AUTOSAR XML (schema 4-2-2)
package /COM_SWC
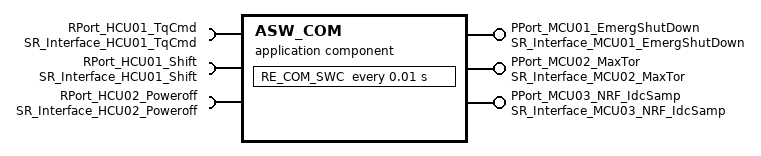
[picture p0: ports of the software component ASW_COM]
  application sw component type ASW_COM
    provide port PPort_MCU01_EmergShutDown: provided-interface=SR_Interface_MCU01_EmergShutDown
    provide port PPort_MCU02_MaxTor: provided-interface=SR_Interface_MCU02_MaxTor
    provide port PPort_MCU03_NRF_IdcSamp: provided-interface=SR_Interface_MCU03_NRF_IdcSamp
    require port RPort_HCU01_TqCmd: nonqueued-receiver-com-spec{alive-timeout=0.3, data-element=HCU01_TqCmd}, required-interface=SR_Interface_HCU01_TqCmd
    require port RPort_HCU01_Shift: nonqueued-receiver-com-spec{alive-timeout=0.3, data-element=HCU01_Shift}, required-interface=SR_Interface_HCU01_Shift
    require port RPort_HCU02_Poweroff: nonqueued-receiver-com-spec{alive-timeout=0.3, data-element=HCU02_Poweroff}, required-interface=SR_Interface_HCU02_Poweroff
    behavior SwcInternalBehavior
      timing event TE_RE_COM_SWC_10ms: start-on-event=RE_COM_SWC, period=0.01
      runnable RE_COM_SWC: symbol=RE_COM_SWC_func
        data-receive-point-by-arguments:
          access DRPA_HCU01_TqCmd_0: accessed-variable=RPort_HCU01_TqCmd.HCU01_TqCmd
          access DRPA_HCU01_Shift_0: accessed-variable=RPort_HCU01_Shift.HCU01_Shift
          access DRPA_HCU02_Poweroff_0: accessed-variable=RPort_HCU02_Poweroff.HCU02_Poweroff
        data-send-points:
          access DSP_MCU01_EmergShutDown_0: accessed-variable=PPort_MCU01_EmergShutDown.MCU01_EmergShutDown
          access DSP_MCU02_MaxTor_0: accessed-variable=PPort_MCU02_MaxTor.MCU02_MaxTor
          access DSP_MCU03_NRF_IdcSamp_0: accessed-variable=PPort_MCU03_NRF_IdcSamp.MCU03_NRF_IdcSamp
